# CH583SFR register map
Vendor: WCH Ltd.; Series: CH58x; File version: 1.1
CPU: RISC-V r0p0, little endian, no MPU, no FPU, 2 interrupt priority bits
Registers are 8-bit, read-write, reset 0x0 unless marked. A register's access mark holds for its fields unless they carry their own. Offsets are from the block's base; [hi:lo] are bit positions; {n}, {i} and the like mark numbered series.

## SPI1
Base 0x40004400
0x00 CTRL_MOD reset 0x2 — RW, SPI1 mode control
  [7] MISO_OE — RW, SPI MISO output enable
  [6] MOSI_OE — RW, SPI MOSI output enable
  [5] SCK_OE — RW, SPI SCK output enable
  [4] FIFO_DIR — RW, SPI FIFO direction: 0=out(write @master mode), 1=in(read @master mode)
  [3] MST_SCK_MOD — RW, SPI master clock mode: 0=mode 0, 1=mode 3
  [3] SLV_CMD_MOD — RW, SPI0 slave command mode: 0=byte stream, 1=first byte command
  [2] TWO_WIRE_MOD — RW, SPI0 enable 2 wire mode for slave: 0=3wire(SCK0,MOSI,MISO), 1=2wire(SCK0,MISO=MXSX)
  [1] ALL_CLEAR — RW, force clear SPI FIFO and count
  [0] MODE_SLAVE — RW, SPI0 slave mode: 0=master or host, 1=slave or device
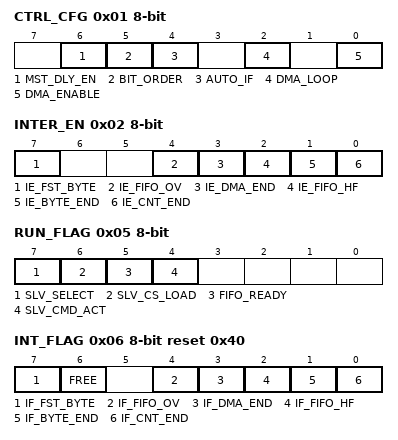
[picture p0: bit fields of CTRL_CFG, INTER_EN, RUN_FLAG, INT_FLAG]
0x01 CTRL_CFG — RW, SPI1 configuration control
  [6] MST_DLY_EN — RW, SPI master input delay enable
  [5] BIT_ORDER — RW, SPI bit data order: 0=MSB first, 1=LSB first
  [4] AUTO_IF — RW, enable buffer/FIFO accessing to auto clear RB_SPI_IF_BYTE_END interrupt flag
  [2] DMA_LOOP — RW, SPI0 DMA address loop enable
  [0] DMA_ENABLE — RW, SPI0 DMA enable
0x02 INTER_EN — RW, SPI1 interrupt enable
  [7] IE_FST_BYTE — RW, enable interrupt for SPI0 slave mode first byte received
  [4] IE_FIFO_OV — RW, enable interrupt for SPI0 FIFO overflow
  [3] IE_DMA_END — RW, enable interrupt for SPI0 DMA completion
  [2] IE_FIFO_HF — RW, enable interrupt for SPI FIFO half
  [1] IE_BYTE_END — RW, enable interrupt for SPI byte exchanged
  [0] IE_CNT_END — RW, enable interrupt for SPI total byte count end
0x03 CLOCK_DIV reset 0x10 — RW, SPI1 master clock divisor
0x03 SLAVE_PRE reset 0x10 — RW, SPI1 slave preset value
0x04 BUFFER — RW, SPI1 data buffer
0x05 RUN_FLAG ro — RO, SPI1 work flag
  [7] SLV_SELECT — RO, SPI0 slave selection status
  [6] SLV_CS_LOAD — RO, SPI0 slave chip-select loading status
  [5] FIFO_READY — RO, SPI FIFO ready status
  [4] SLV_CMD_ACT — RO, SPI0 slave first byte or command flag
0x06 INT_FLAG reset 0x40 — RW1, SPI1 interrupt flag
  [7] IF_FST_BYTE — RW1, interrupt flag for SPI0 slave mode first byte received
  [6] FREE — RO, current SPI free status
  [4] IF_FIFO_OV — RW1, interrupt flag for SPI0 FIFO overflow
  [3] IF_DMA_END — RW1, interrupt flag for SPI0 DMA completion
  [2] IF_FIFO_HF — RW1, interrupt flag for SPI FIFO half
  [1] IF_BYTE_END — RW1, interrupt flag for SPI byte exchanged
  [0] IF_CNT_END — RW1, interrupt flag for SPI total byte count end
0x07 FIFO_COUNT ro — RO, SPI1 FIFO count status
  [7:0] FIFO_COUNT — RO, SPI0 FIFO count status
0x0C TOTAL_CNT 16-bit — RW, SPI1 total byte count, only low 12 bit
0x10 FIFO — RO/WO, SPI1 FIFO register
0x13 FIFO_COUNT1 ro — RO, SPI1 FIFO count status

## PWMx
Base 0x40005000
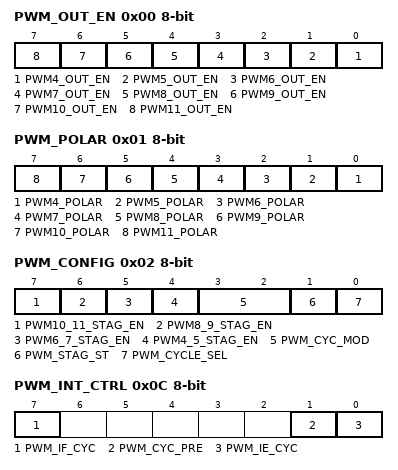
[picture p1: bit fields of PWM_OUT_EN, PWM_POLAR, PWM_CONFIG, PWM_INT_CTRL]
0x00 PWM_OUT_EN — RW, PWM output enable control
  [n-4] PWM{n}_OUT_EN (n=4..11) — RW, PWM{n} output enable
0x01 PWM_POLAR — RW, PWM output polarity control
  [n-4] PWM{n}_POLAR (n=4..11) — RW, PWM{n} output polarity: 0=default low and high action, 1=default high and low action
0x02 PWM_CONFIG (reset mask 0xF0) — RW, PWM configuration
  [7] PWM10_11_STAG_EN — RW, PWM10/11 stagger output enable: 0=independent output, 1=stagger output
  [6] PWM8_9_STAG_EN — RW, PWM8/9 stagger output enable: 0=independent output, 1=stagger output
  [5] PWM6_7_STAG_EN — RW, PWM6/7 stagger output enable: 0=independent output, 1=stagger output
  [4] PWM4_5_STAG_EN — RW, PWM4/5 stagger output enable: 0=independent output, 1=stagger output
  [3:2] PWM_CYC_MOD — RW, PWM data width mode: 00=8 bits data, 01=7 bits data, 10=6 bits data, 11=5 bits data
  [1] PWM_STAG_ST ro — RO, PWM stagger cycle status
  [0] PWM_CYCLE_SEL — RW, PWM cycle selection: 0=256;128;64;32 clocks, 1=255;127;63;31 clocks
0x03 PWM_CLOCK_DIV — RW, PWM clock divisor
{0x0+i} PWM{i}_DATA (i=4..11) — RW, PWM{i} data holding
0x0C PWM_INT_CTRL — RW, PWM interrupt control
  [7] PWM_IF_CYC — RW1, interrupt flag for PWM cycle end
  [1] PWM_CYC_PRE — RW, select PWM cycle interrupt point
  [0] PWM_IE_CYC — RW, enable interrupt for PWM cycle end
